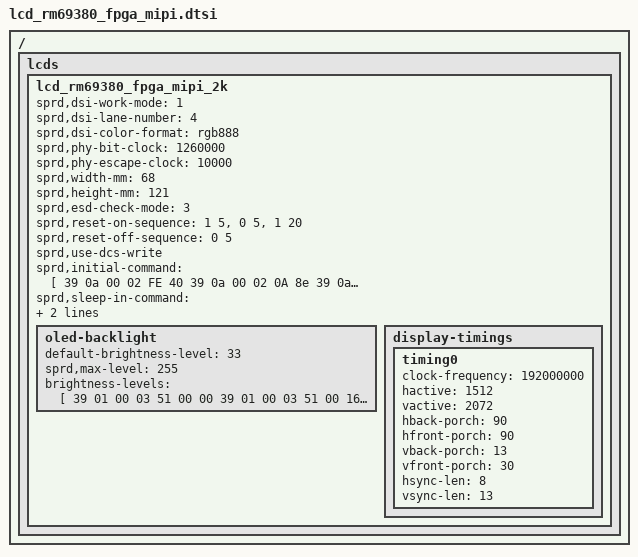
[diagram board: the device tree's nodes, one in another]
/ { lcds {
	lcd_rm69380_fpga_mipi_2k: lcd_rm69380_fpga_mipi_2k {

		sprd,dsi-work-mode = <1>; /* video burst mode*/
		sprd,dsi-lane-number = <4>;
		sprd,dsi-color-format = "rgb888";
		/* 1200*2560 @ 60fps */
		sprd,phy-bit-clock = <1260000>;  /* kbps */
		sprd,phy-escape-clock = <10000>;/* kHz */

		sprd,width-mm = <68>;
		sprd,height-mm = <121>;

		sprd,esd-check-mode = <3>;

		sprd,reset-on-sequence = <1 5>, <0 5>, <1 20>;
		sprd,reset-off-sequence = <0 5>;
	        /*sprd,fpga-logic-reset-sequence = <1 1>, <0 1>, <1 1>; */

		sprd,use-dcs-write;
   	sprd,initial-command = [
		
                39 0a 00 02 FE 40
                39 0a 00 02 0A 8e
                39 0a 00 02 0B 11 
                ];

		sprd,sleep-in-command = [
			13 0A 00 01 28
			13 78 00 01 10
			];
		sprd,sleep-out-command = [
			];


        oled-backlight {
            default-brightness-level = <33>;
            sprd,max-level = <255>;

            brightness-levels = [
			39 01 00 03 51 00 00
			39 01 00 03 51 00 16
			39 01 00 03 51 00 1c
			39 01 00 03 51 00 22
			39 01 00 03 51 00 28
			39 01 00 03 51 00 2D
			39 01 00 03 51 00 35
			39 01 00 03 51 00 3D
			39 01 00 03 51 00 45
			39 01 00 03 51 00 4D
			39 01 00 03 51 00 55
			39 01 00 03 51 00 5D
			39 01 00 03 51 00 65
			39 01 00 03 51 00 6D
			39 01 00 03 51 00 75
			39 01 00 03 51 00 7D
			39 01 00 03 51 00 85
			39 01 00 03 51 00 8D
			39 01 00 03 51 00 95
			39 01 00 03 51 00 9D
			39 01 00 03 51 00 A5
			39 01 00 03 51 00 AD
			39 01 00 03 51 00 B5
			39 01 00 03 51 00 BD
			39 01 00 03 51 00 C5
			39 01 00 03 51 00 CD
			39 01 00 03 51 00 D5
			39 01 00 03 51 00 DD
			39 01 00 03 51 00 E5
			39 01 00 03 51 00 ED
			39 01 00 03 51 00 F5
			39 01 00 03 51 00 FD
			39 01 00 03 51 01 05
			39 01 00 03 51 01 0D
			39 01 00 03 51 01 15
			39 01 00 03 51 01 1D
			39 01 00 03 51 01 25
			39 01 00 03 51 01 2D
			39 01 00 03 51 01 35
			39 01 00 03 51 01 3D
			39 01 00 03 51 01 45
			39 01 00 03 51 01 4D
			39 01 00 03 51 01 55
			39 01 00 03 51 01 5D
			39 01 00 03 51 01 65
			39 01 00 03 51 01 6D
			39 01 00 03 51 01 75
			39 01 00 03 51 01 7D
			39 01 00 03 51 01 85
			39 01 00 03 51 01 8D
			39 01 00 03 51 01 95
			39 01 00 03 51 01 9D
			39 01 00 03 51 01 A5
			39 01 00 03 51 01 AD
			39 01 00 03 51 01 B5
			39 01 00 03 51 01 BD
			39 01 00 03 51 01 C5
			39 01 00 03 51 01 CD
			39 01 00 03 51 01 D5
			39 01 00 03 51 01 DD
			39 01 00 03 51 01 E5
			39 01 00 03 51 01 ED
			39 01 00 03 51 01 F5
			39 01 00 03 51 01 FD
			39 01 00 03 51 02 05
			39 01 00 03 51 02 0D
			39 01 00 03 51 02 15
			39 01 00 03 51 02 1D
			39 01 00 03 51 02 25
			39 01 00 03 51 02 2D
			39 01 00 03 51 02 35
			39 01 00 03 51 02 3D
			39 01 00 03 51 02 45
			39 01 00 03 51 02 4D
			39 01 00 03 51 02 55
			39 01 00 03 51 02 5D
			39 01 00 03 51 02 65
			39 01 00 03 51 02 6D
			39 01 00 03 51 02 75
			39 01 00 03 51 02 7D
			39 01 00 03 51 02 85
			39 01 00 03 51 02 8D
			39 01 00 03 51 02 95
			39 01 00 03 51 02 9D
			39 01 00 03 51 02 A5
			39 01 00 03 51 02 AD
			39 01 00 03 51 02 B5
			39 01 00 03 51 02 BD
			39 01 00 03 51 02 C5
			39 01 00 03 51 02 CD
			39 01 00 03 51 02 D5
			39 01 00 03 51 02 DD
			39 01 00 03 51 02 E5
			39 01 00 03 51 02 ED
			39 01 00 03 51 02 F5
			39 01 00 03 51 02 FD
			39 01 00 03 51 03 05
			39 01 00 03 51 03 0D
			39 01 00 03 51 03 15
			39 01 00 03 51 03 1D
			39 01 00 03 51 03 25
			39 01 00 03 51 03 2D
			39 01 00 03 51 03 35
			39 01 00 03 51 03 3D
			39 01 00 03 51 03 45
			39 01 00 03 51 03 4D
			39 01 00 03 51 03 55
			39 01 00 03 51 03 5D
			39 01 00 03 51 03 65
			39 01 00 03 51 03 6D
			39 01 00 03 51 03 75
			39 01 00 03 51 03 7D
			39 01 00 03 51 03 85
			39 01 00 03 51 03 8D
			39 01 00 03 51 03 95
			39 01 00 03 51 03 9D
			39 01 00 03 51 03 A5
			39 01 00 03 51 03 AD
			39 01 00 03 51 03 B5
			39 01 00 03 51 03 BD
			39 01 00 03 51 03 C5
			39 01 00 03 51 03 CD
			39 01 00 03 51 03 D5
			39 01 00 03 51 03 DD
			39 01 00 03 51 03 E5
			39 01 00 03 51 03 ED
			39 01 00 03 51 03 F5
			39 01 00 03 51 03 FD
			39 01 00 03 51 04 05
			39 01 00 03 51 04 0D
			39 01 00 03 51 04 15
			39 01 00 03 51 04 1D
			39 01 00 03 51 04 25
			39 01 00 03 51 04 2D
			39 01 00 03 51 04 35
			39 01 00 03 51 04 3D
			39 01 00 03 51 04 45
			39 01 00 03 51 04 4D
			39 01 00 03 51 04 55
			39 01 00 03 51 04 5D
			39 01 00 03 51 04 65
			39 01 00 03 51 04 6D
			39 01 00 03 51 04 75
			39 01 00 03 51 04 7D
			39 01 00 03 51 04 85
			39 01 00 03 51 04 8D
			39 01 00 03 51 04 95
			39 01 00 03 51 04 9D
			39 01 00 03 51 04 A5
			39 01 00 03 51 04 AD
			39 01 00 03 51 04 B5
			39 01 00 03 51 04 BD
			39 01 00 03 51 04 C5
			39 01 00 03 51 04 CD
			39 01 00 03 51 04 D5
			39 01 00 03 51 04 DD
			39 01 00 03 51 04 E5
			39 01 00 03 51 04 ED
			39 01 00 03 51 04 F5
			39 01 00 03 51 04 FD
			39 01 00 03 51 05 05
			39 01 00 03 51 05 0D
			39 01 00 03 51 05 15
			39 01 00 03 51 05 1D
			39 01 00 03 51 05 25
			39 01 00 03 51 05 2D
			39 01 00 03 51 05 35
			39 01 00 03 51 05 3D
			39 01 00 03 51 05 45
			39 01 00 03 51 05 4D
			39 01 00 03 51 05 55
			39 01 00 03 51 05 5D
			39 01 00 03 51 05 65
			39 01 00 03 51 05 6D
			39 01 00 03 51 05 75
			39 01 00 03 51 05 7D
			39 01 00 03 51 05 85
			39 01 00 03 51 05 8D
			39 01 00 03 51 05 95
			39 01 00 03 51 05 9D
			39 01 00 03 51 05 A5
			39 01 00 03 51 05 AD
			39 01 00 03 51 05 B5
			39 01 00 03 51 05 BD
			39 01 00 03 51 05 C5
			39 01 00 03 51 05 CD
			39 01 00 03 51 05 D5
			39 01 00 03 51 05 DD
			39 01 00 03 51 05 E5
			39 01 00 03 51 05 ED
			39 01 00 03 51 05 F5
			39 01 00 03 51 05 FD
			39 01 00 03 51 06 05
			39 01 00 03 51 06 0D
			39 01 00 03 51 06 15
			39 01 00 03 51 06 1D
			39 01 00 03 51 06 25
			39 01 00 03 51 06 2D
			39 01 00 03 51 06 35
			39 01 00 03 51 06 3D
			39 01 00 03 51 06 45
			39 01 00 03 51 06 4D
			39 01 00 03 51 06 55
			39 01 00 03 51 06 5D
			39 01 00 03 51 06 65
			39 01 00 03 51 06 6D
			39 01 00 03 51 06 75
			39 01 00 03 51 06 7D
			39 01 00 03 51 06 85
			39 01 00 03 51 06 8D
			39 01 00 03 51 06 95
			39 01 00 03 51 06 9D
			39 01 00 03 51 06 A5
			39 01 00 03 51 06 AD
			39 01 00 03 51 06 B5
			39 01 00 03 51 06 BD
			39 01 00 03 51 06 C5
			39 01 00 03 51 06 CD
			39 01 00 03 51 06 D5
			39 01 00 03 51 06 DD
			39 01 00 03 51 06 E5
			39 01 00 03 51 06 ED
			39 01 00 03 51 06 F5
			39 01 00 03 51 06 FD
			39 01 00 03 51 07 05
			39 01 00 03 51 07 0D
			39 01 00 03 51 07 15
			39 01 00 03 51 07 1D
			39 01 00 03 51 07 25
			39 01 00 03 51 07 2D
			39 01 00 03 51 07 35
			39 01 00 03 51 07 3D
			39 01 00 03 51 07 45
			39 01 00 03 51 07 4D
			39 01 00 03 51 07 55
			39 01 00 03 51 07 5D
			39 01 00 03 51 07 65
			39 01 00 03 51 07 6D
			39 01 00 03 51 07 75
			39 01 00 03 51 07 7D
			39 01 00 03 51 07 85
			39 01 00 03 51 07 8D
			39 01 00 03 51 07 95
			39 01 00 03 51 07 9D
			39 01 00 03 51 07 A5
			39 01 00 03 51 07 AD
			39 01 00 03 51 07 B5
			39 01 00 03 51 07 BD
			39 01 00 03 51 07 C5
			39 01 00 03 51 07 CD
			39 01 00 03 51 07 D5
			39 01 00 03 51 07 DD
			39 01 00 03 51 07 E5
			39 01 00 03 51 07 ED
			39 01 00 03 51 07 F5
			39 01 00 03 51 07 FF
                    ];
        };

		#if 1
		/* 1200*2560 @ 60fps */
		display-timings {
			timing0 {
				clock-frequency = <192000000>;
				hactive = <1512>;
				vactive = <2072>;
				hback-porch = <90>;
				hfront-porch = <90>;
				vback-porch = <13>;
				vfront-porch = <30>;
				hsync-len = <8>;
				vsync-len = <13>;
			};
		};
		#endif
	};
};};
